# N32G41x register map
Vendor: Nsingtech Ltd.; File version: 1.0
CPU: CM4 r0p1, little endian, no MPU, no FPU, 4 interrupt priority bits
Registers are 32-bit, read-write, reset 0x0 unless marked. A register's access mark holds for its fields unless they carry their own. Offsets are from the block's base; [hi:lo] are bit positions; {n}, {i} and the like mark numbered series.

## EXTI — External Interrupt/Event Controller
Base 0x40010400
0x00 EXTI_EMASK — EXTI Event Mask Register
  [25:0] EMASK — Event mask for line x
0x04 EXTI_IMASK — EXTI Interrupt Mask Register
  [25:0] IMASK — Interrupt mask for line x
0x08 EXTI_FT_CFG — EXTI Falling Trigger Configuration Register
  [25:0] FT_CFG — Falling trigger for line x
0x0C EXTI_RT_CFG — EXTI Rising Trigger Configuration Register
  [25:0] RT_CFG — Rising trigger for line x
0x10 EXTI_PEND — EXTI Pending Register
  [25:0] PEND — Pending bit for line x
0x14 EXTI_SWIE — EXTI Software Interrupt Event Register
  [25:0] SWIE — Software interrupt for line x
0x18 EXTI_TS_SEL — EXTI Timestamp Trigger Selection Register
  [3:0] TSSEL — Timestamp trigger source selection

## GPIOA — GPIO Port A
Base 0x40021400
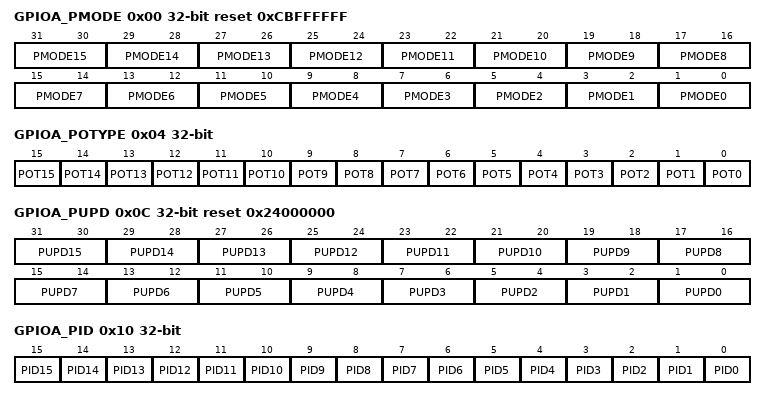
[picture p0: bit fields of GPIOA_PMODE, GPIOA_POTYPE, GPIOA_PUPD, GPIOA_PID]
0x00 GPIOA_PMODE reset 0xCBFFFFFF — GPIOA Port Mode Register
  [2n+1:2n] PMODE{n} (n=0..15) — Port A mode for pin {n}
0x04 GPIOA_POTYPE — GPIOA Port Output Type Register
  [n] POT{n} (n=0..15) — Port A output type for pin {n}
0x0C GPIOA_PUPD reset 0x24000000 — GPIOA Port Pull-Up/Pull-Down Register
  [2n+1:2n] PUPD{n} (n=0..15) — Port A pull-up/pull-down for pin {n}
0x10 GPIOA_PID ro — GPIOA Port Input Data Register
  [n] PID{n} (n=0..15) — Port A input data for pin {n}
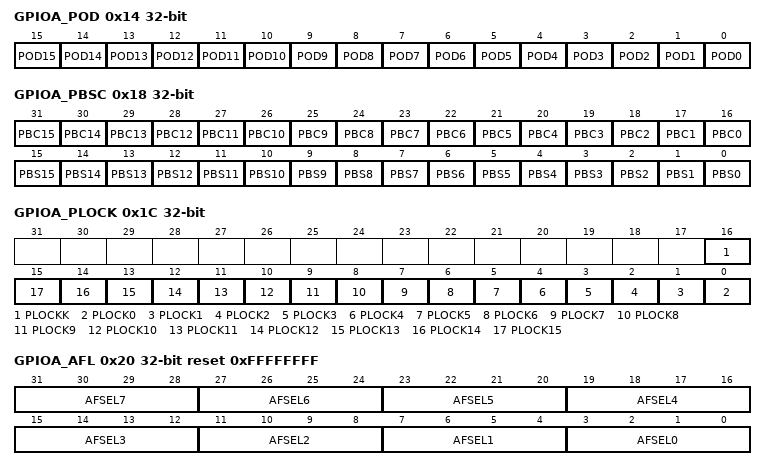
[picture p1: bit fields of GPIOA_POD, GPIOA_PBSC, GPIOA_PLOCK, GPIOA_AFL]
0x14 GPIOA_POD — GPIOA Port Output Data Register
  [n] POD{n} (n=0..15) — Port A output data for pin {n}
0x18 GPIOA_PBSC wo — GPIOA Port Bit Set/Clear Register
  [n+16] PBC{n} (n=0..15) — Port A clear bit {n}
  [n] PBS{n} (n=0..15) — Port A set bit {n}
0x1C GPIOA_PLOCK — GPIOA Port Configuration Lock Register
  [16] PLOCKK — Port configuration lock key
  [n] PLOCK{n} (n=0..15) — Port A configuration lock for pin {n}
0x20 GPIOA_AFL reset 0xFFFFFFFF — GPIOA Alternate Function Low Register
  [4n+3:4n] AFSEL{n} (n=0..7) — Port A alternate function for pin {n}
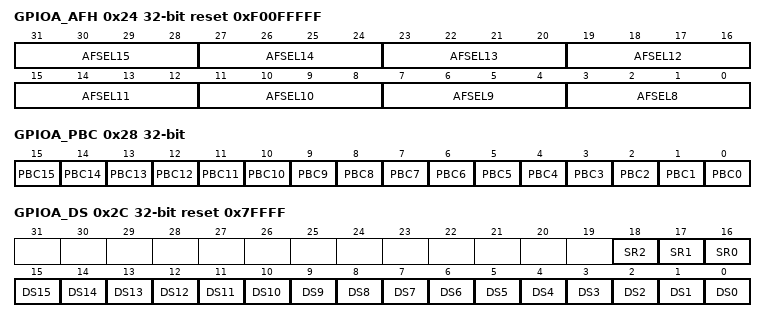
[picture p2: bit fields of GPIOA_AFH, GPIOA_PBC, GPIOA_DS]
0x24 GPIOA_AFH reset 0xF00FFFFF — GPIOA Alternate Function High Register
  [4n-29:4n-32] AFSEL{n} (n=8..15) — Port A alternate function for pin {n}
0x28 GPIOA_PBC wo — GPIOA Port Bit Clear Register
  [n] PBC{n} (n=0..15) — Port A clear output bit {n}
0x2C GPIOA_DS reset 0x7FFFF — GPIOA Drive Strength Register
  [18] SR2 — Slew rate control PA2
  [17] SR1 — Slew rate control PA1
  [16] SR0 — Slew rate control PA0
  [n] DS{n} (n=0..15) — Port A drive strength for pin {n}

## GPIOB — GPIO Port B
Base 0x40021500
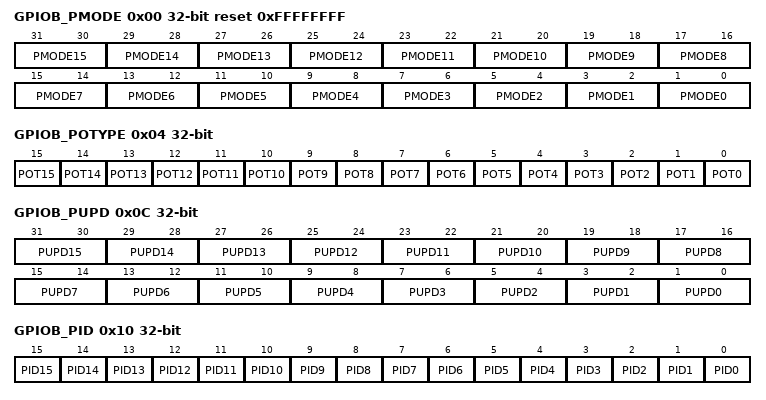
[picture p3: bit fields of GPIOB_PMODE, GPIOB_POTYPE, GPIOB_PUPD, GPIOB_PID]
0x00 GPIOB_PMODE reset 0xFFFFFFFF — GPIOB Port Mode Register
  [2n+1:2n] PMODE{n} (n=0..15) — Port B mode for pin {n}
0x04 GPIOB_POTYPE — GPIOB Port Output Type Register
  [n] POT{n} (n=0..15) — Port B output type for pin {n}
0x0C GPIOB_PUPD — GPIOB Port Pull-Up/Pull-Down Register
  [2n+1:2n] PUPD{n} (n=0..15) — Port B pull-up/pull-down for pin {n}
0x10 GPIOB_PID ro — GPIOB Port Input Data Register
  [n] PID{n} (n=0..15) — Port B input data for pin {n}
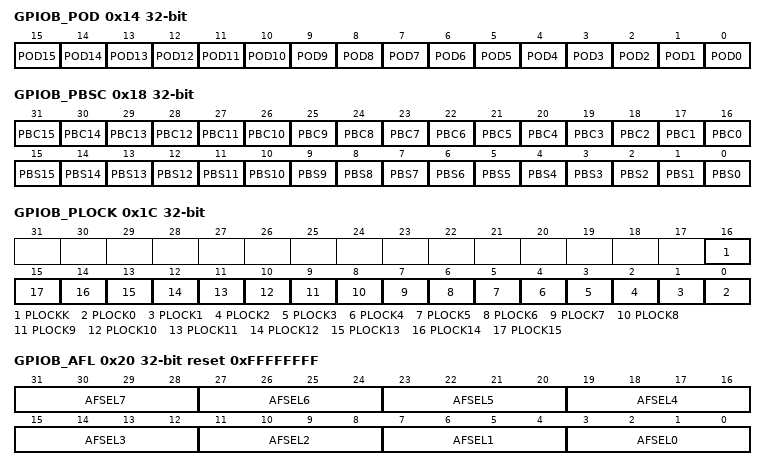
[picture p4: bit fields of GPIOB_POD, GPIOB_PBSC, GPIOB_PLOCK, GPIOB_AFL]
0x14 GPIOB_POD — GPIOB Port Output Data Register
  [n] POD{n} (n=0..15) — Port B output data for pin {n}
0x18 GPIOB_PBSC wo — GPIOB Port Bit Set/Clear Register
  [n+16] PBC{n} (n=0..15) — Port B clear bit {n}
  [n] PBS{n} (n=0..15) — Port B set bit {n}
0x1C GPIOB_PLOCK — GPIOB Port Configuration Lock Register
  [16] PLOCKK — Port configuration lock key
  [n] PLOCK{n} (n=0..15) — Port B configuration lock for pin {n}
0x20 GPIOB_AFL reset 0xFFFFFFFF — GPIOB Alternate Function Low Register
  [4n+3:4n] AFSEL{n} (n=0..7) — Port B alternate function for pin {n}
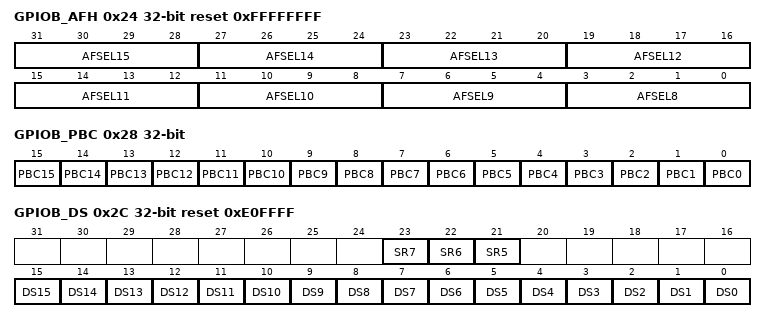
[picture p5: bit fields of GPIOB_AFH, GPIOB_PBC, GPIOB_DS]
0x24 GPIOB_AFH reset 0xFFFFFFFF — GPIOB Alternate Function High Register
  [4n-29:4n-32] AFSEL{n} (n=8..15) — Port B alternate function for pin {n}
0x28 GPIOB_PBC wo — GPIOB Port Bit Clear Register
  [n] PBC{n} (n=0..15) — Port B clear output bit {n}
0x2C GPIOB_DS reset 0xE0FFFF — GPIOB Drive Strength Register
  [23] SR7 — Slew rate control PB7
  [22] SR6 — Slew rate control PB6
  [21] SR5 — Slew rate control PB5
  [n] DS{n} (n=0..15) — Port B drive strength for pin {n}
